# N32L406 register map
Vendor: Nsing Technologies Pte. Ltd.; File version: 1.0
Registers are 32-bit, read-write, reset 0x0 unless marked. A register's access mark holds for its fields unless they carry their own. Offsets are from the block's base; [hi:lo] are bit positions; {n}, {i} and the like mark numbered series.

## AFIO — Alternate function I/O
Base 0x40010000
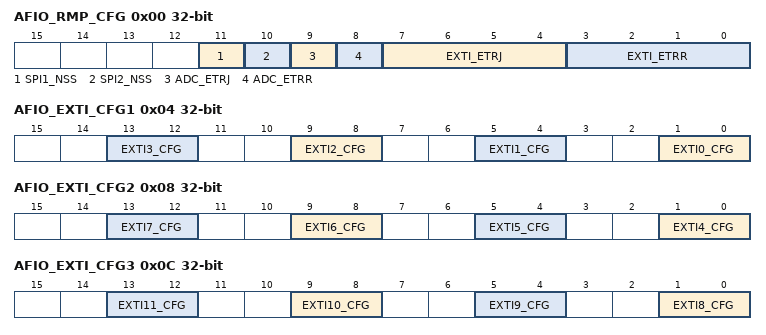
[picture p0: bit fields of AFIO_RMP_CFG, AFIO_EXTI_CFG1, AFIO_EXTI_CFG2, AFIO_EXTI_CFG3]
0x00 AFIO_RMP_CFG
  [11] SPI1_NSS, [10] SPI2_NSS, [9] ADC_ETRJ, [8] ADC_ETRR, [7:4] EXTI_ETRJ, [3:0] EXTI_ETRR
0x04 AFIO_EXTI_CFG1
  [4n+1:4n] EXTI{n}_CFG (n=0..3)
0x08 AFIO_EXTI_CFG2
  [4n-15:4n-16] EXTI{n}_CFG (n=4..7)
0x0C AFIO_EXTI_CFG3
  [4n-31:4n-32] EXTI{n}_CFG (n=8..11)
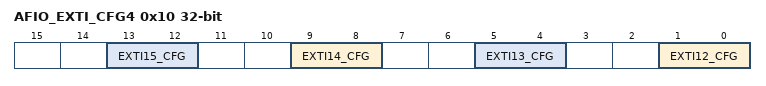
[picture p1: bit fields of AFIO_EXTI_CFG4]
0x10 AFIO_EXTI_CFG4
  [4n-47:4n-48] EXTI{n}_CFG (n=12..15)

## I2C1 — Inter integrated circuit
Base 0x40005400
Same registers: I2C2 0x40005800
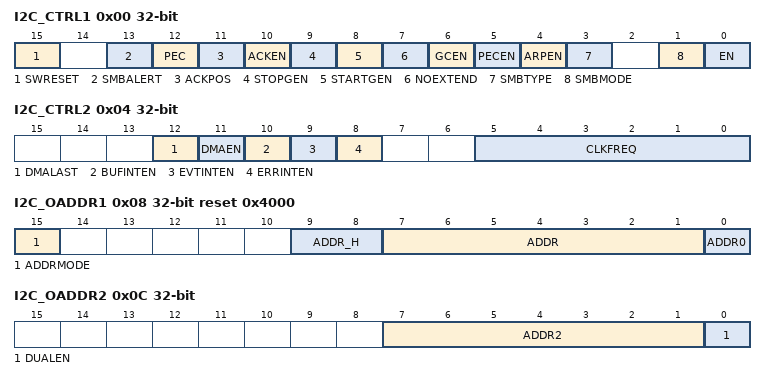
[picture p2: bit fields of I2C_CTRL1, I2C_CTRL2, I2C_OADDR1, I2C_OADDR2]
0x00 I2C_CTRL1
  [15] SWRESET, [13] SMBALERT, [12] PEC, [11] ACKPOS, [10] ACKEN, [9] STOPGEN, [8] STARTGEN, [7] NOEXTEND, [6] GCEN, [5] PECEN, [4] ARPEN, [3] SMBTYPE, [1] SMBMODE, [0] EN
0x04 I2C_CTRL2
  [12] DMALAST, [11] DMAEN, [10] BUFINTEN, [9] EVTINTEN, [8] ERRINTEN, [5:0] CLKFREQ
0x08 I2C_OADDR1 reset 0x4000
  [15] ADDRMODE, [9:8] ADDR_H, [7:1] ADDR, [0] ADDR0
0x0C I2C_OADDR2
  [7:1] ADDR2, [0] DUALEN
0x10 I2C_DAT
  [7:0] DATA
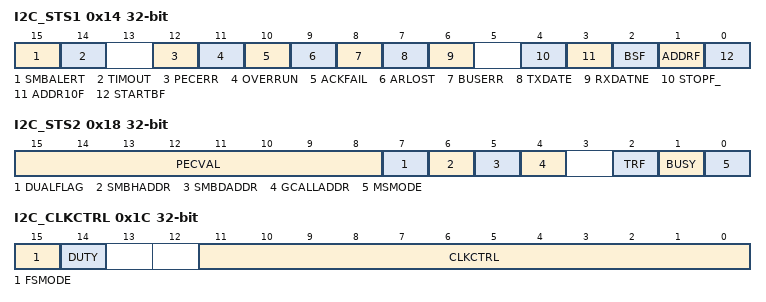
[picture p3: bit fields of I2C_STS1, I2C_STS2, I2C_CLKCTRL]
0x14 I2C_STS1
  [15] SMBALERT, [14] TIMOUT, [12] PECERR, [11] OVERRUN, [10] ACKFAIL, [9] ARLOST, [8] BUSERR, [7] TXDATE, [6] RXDATNE, [4] STOPF_, [3] ADDR10F, [2] BSF, [1] ADDRF, [0] STARTBF
0x18 I2C_STS2
  [15:8] PECVAL, [7] DUALFLAG, [6] SMBHADDR, [5] SMBDADDR, [4] GCALLADDR, [2] TRF, [1] BUSY, [0] MSMODE
0x1C I2C_CLKCTRL
  [15] FSMODE, [14] DUTY, [11:0] CLKCTRL
0x20 I2C_TMRISE
  [5:0] TMRISE

## IWDG — Independent watchdog
Base 0x40003000
0x00 IWDG_KEY
  [15:0] KEYV
0x04 IWDG_PREDIV
  [2:0] PD
0x08 IWDG_RELV reset 0xFFF
  [11:0] REL
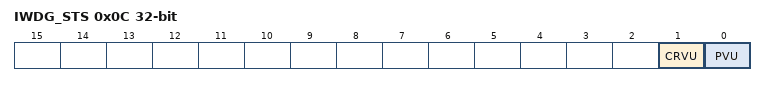
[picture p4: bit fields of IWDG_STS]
0x0C IWDG_STS
  [1] CRVU, [0] PVU

## LCD — Liquid Crystal Display
Base 0x40004000
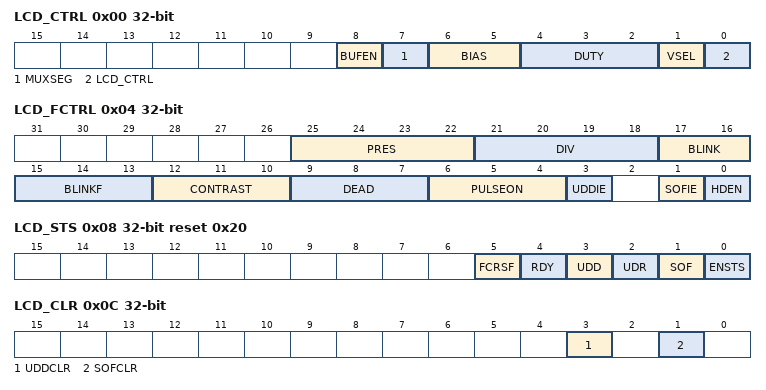
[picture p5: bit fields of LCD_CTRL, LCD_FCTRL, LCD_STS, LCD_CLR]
0x00 LCD_CTRL
  [8] BUFEN, [7] MUXSEG, [6:5] BIAS, [4:2] DUTY, [1] VSEL, [0] LCD_CTRL
0x04 LCD_FCTRL
  [25:22] PRES, [21:18] DIV, [17:16] BLINK, [15:13] BLINKF, [12:10] CONTRAST, [9:7] DEAD, [6:4] PULSEON, [3] UDDIE, [1] SOFIE, [0] HDEN
0x08 LCD_STS reset 0x20
  [5] FCRSF, [4] RDY, [3] UDD, [2] UDR, [1] SOF, [0] ENSTS
0x0C LCD_CLR
  [3] UDDCLR, [1] SOFCLR
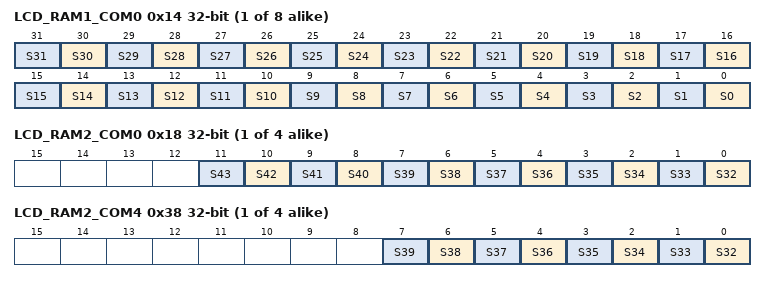
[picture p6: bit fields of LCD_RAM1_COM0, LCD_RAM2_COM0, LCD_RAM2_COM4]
{0x14+8i} LCD_RAM1_COM{i} (i=0..7)
  [n] S{n} (n=0..31)
{0x18+8i} LCD_RAM2_COM{i} (i=0..3)
  [n-32] S{n} (n=32..43)
{0x18+8i} LCD_RAM2_COM{i} (i=4..7)
  [n-32] S{n} (n=32..39)

## LPTIM — Low power timer control
Base 0x40004C00
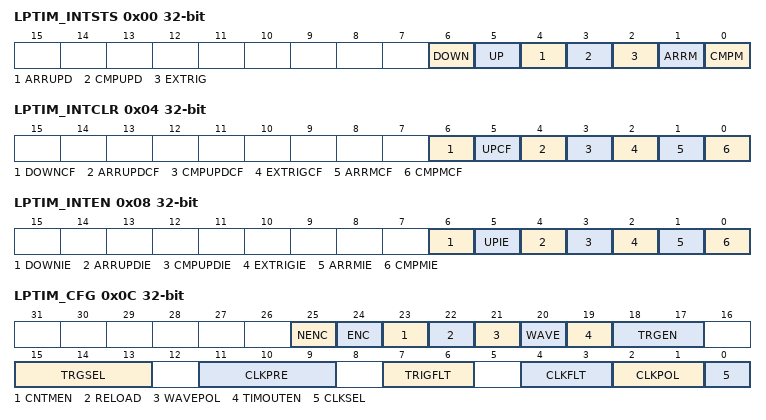
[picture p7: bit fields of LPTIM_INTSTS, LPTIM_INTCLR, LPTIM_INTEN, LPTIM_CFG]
0x00 LPTIM_INTSTS read
  [6] DOWN, [5] UP, [4] ARRUPD, [3] CMPUPD, [2] EXTRIG, [1] ARRM, [0] CMPM
0x04 LPTIM_INTCLR write
  [6] DOWNCF, [5] UPCF, [4] ARRUPDCF, [3] CMPUPDCF, [2] EXTRIGCF, [1] ARRMCF, [0] CMPMCF
0x08 LPTIM_INTEN
  [6] DOWNIE, [5] UPIE, [4] ARRUPDIE, [3] CMPUPDIE, [2] EXTRIGIE, [1] ARRMIE, [0] CMPMIE
0x0C LPTIM_CFG (reset mask 0x3FEEEEF)
  [25] NENC, [24] ENC, [23] CNTMEN, [22] RELOAD, [21] WAVEPOL, [20] WAVE, [19] TIMOUTEN, [18:17] TRGEN, [15:13] TRGSEL, [11:9] CLKPRE, [7:6] TRIGFLT, [4:3] CLKFLT, [2:1] CLKPOL, [0] CLKSEL
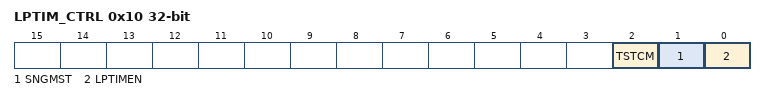
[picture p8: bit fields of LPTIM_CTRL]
0x10 LPTIM_CTRL
  [2] TSTCM, [1] SNGMST, [0] LPTIMEN
0x14 LPTIM_CMP
  [15:0] CMPVAL
0x18 LPTIM_ARR reset 0x1
  [15:0] ARRVAL
0x1C LPTIM_CNT reset 0x1
  [15:0] CNTVAL

## LPUART — Low-power universal asynchronous receiver transmitter
Base 0x40005000
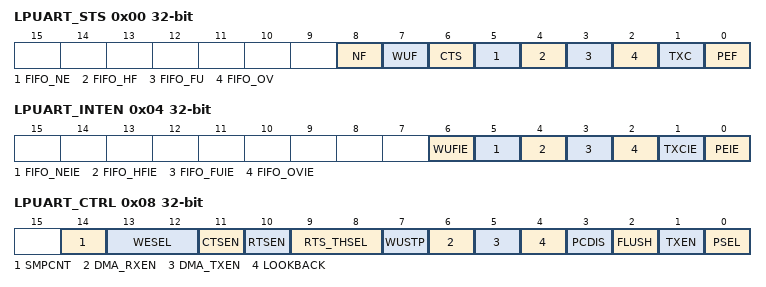
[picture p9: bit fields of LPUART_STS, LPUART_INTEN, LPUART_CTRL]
0x00 LPUART_STS
  [8] NF, [7] WUF, [6] CTS, [5] FIFO_NE, [4] FIFO_HF, [3] FIFO_FU, [2] FIFO_OV, [1] TXC, [0] PEF
0x04 LPUART_INTEN
  [6] WUFIE, [5] FIFO_NEIE, [4] FIFO_HFIE, [3] FIFO_FUIE, [2] FIFO_OVIE, [1] TXCIE, [0] PEIE
0x08 LPUART_CTRL
  [14] SMPCNT, [13:12] WESEL, [11] CTSEN, [10] RTSEN, [9:8] RTS_THSEL, [7] WUSTP, [6] DMA_RXEN, [5] DMA_TXEN, [4] LOOKBACK, [3] PCDIS, [2] FLUSH, [1] TXEN, [0] PSEL
0x0C LPUART_BRCFG1 reset 0x174
  [15:0] INTEGER
0x10 LPUART_DAT
  [7:0] DAT
0x14 LPUART_BRCFG2
  [7:0] DECIMAL
0x18 LPUART_WUDAT

## OPAMP — operational amplifier
Base 0x40002000
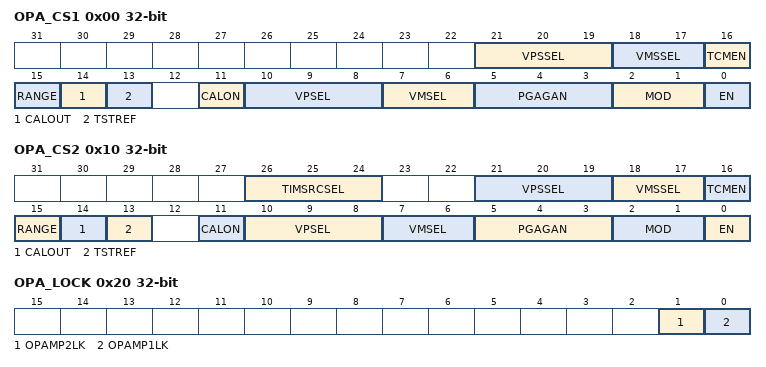
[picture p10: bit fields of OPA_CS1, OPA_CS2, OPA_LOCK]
0x00 OPA_CS1
  [21:19] VPSSEL, [18:17] VMSSEL, [16] TCMEN, [15] RANGE, [14] CALOUT, [13] TSTREF, [11] CALON, [10:8] VPSEL, [7:6] VMSEL, [5:3] PGAGAN, [2:1] MOD, [0] EN
0x10 OPA_CS2 (reset mask 0x3FFFFF)
  [26:24] TIMSRCSEL, [21:19] VPSSEL, [18:17] VMSSEL, [16] TCMEN, [15] RANGE, [14] CALOUT, [13] TSTREF, [11] CALON, [10:8] VPSEL, [7:6] VMSEL, [5:3] PGAGAN, [2:1] MOD, [0] EN
0x20 OPA_LOCK
  [1] OPAMP2LK, [0] OPAMP1LK
